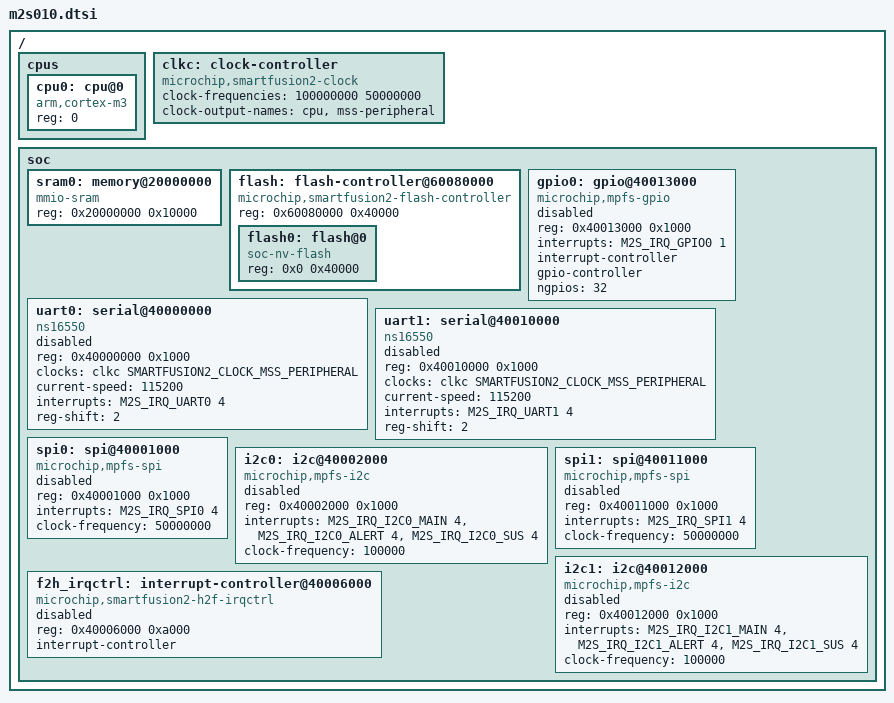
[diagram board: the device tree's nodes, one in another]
/*
 * SPDX-FileCopyrightText: Copyright Bavariamatic GmbH
 * SPDX-License-Identifier: Apache-2.0
 */

#include <arm/armv7-m.dtsi>
#include <zephyr/dt-bindings/clock/microchip-smartfusion2-clock.h>
#include <zephyr/dt-bindings/interrupt-controller/microchip-smartfusion2-irq.h>

/ {
	#address-cells = <1>;
	#size-cells = <1>;

	cpus {
		#address-cells = <1>;
		#size-cells = <0>;

		cpu0: cpu@0 {
			device_type = "cpu";
			compatible = "arm,cortex-m3";
			reg = <0>;
		};
	};

	clkc: clock-controller {
		compatible = "microchip,smartfusion2-clock";
		#clock-cells = <1>;
		clock-frequencies = <100000000 50000000>;
		clock-output-names = "cpu", "mss-peripheral";
	};

	soc {
		sram0: memory@20000000 {
			compatible = "mmio-sram";
			reg = <0x20000000 0x10000>;
		};

		flash: flash-controller@60080000 {
			compatible = "microchip,smartfusion2-flash-controller";
			reg = <0x60080000 0x40000>;
			#address-cells = <1>;
			#size-cells = <1>;
			ranges = <0x0 0x0 0x40000>;

			flash0: flash@0 {
				compatible = "soc-nv-flash";
				reg = <0x0 0x40000>;
				#address-cells = <1>;
				#size-cells = <1>;
				ranges = <0x0 0x0 0x40000>;
			};
		};

		gpio0: gpio@40013000 {
			compatible = "microchip,mpfs-gpio";
			reg = <0x40013000 0x1000>;
			interrupts = <M2S_IRQ_GPIO0 1>;
			interrupt-controller;
			#address-cells = <0>;
			#interrupt-cells = <1>;
			gpio-controller;
			#gpio-cells = <2>;
			ngpios = <32>;
			status = "disabled";
		};

		uart0: serial@40000000 {
			compatible = "ns16550";
			reg = <0x40000000 0x1000>;
			clocks = <&clkc SMARTFUSION2_CLOCK_MSS_PERIPHERAL>;
			current-speed = <115200>;
			interrupts = <M2S_IRQ_UART0 4>;
			reg-shift = <2>;
			status = "disabled";
		};

		uart1: serial@40010000 {
			compatible = "ns16550";
			reg = <0x40010000 0x1000>;
			clocks = <&clkc SMARTFUSION2_CLOCK_MSS_PERIPHERAL>;
			current-speed = <115200>;
			interrupts = <M2S_IRQ_UART1 4>;
			reg-shift = <2>;
			status = "disabled";
		};

		spi0: spi@40001000 {
			compatible = "microchip,mpfs-spi";
			reg = <0x40001000 0x1000>;
			interrupts = <M2S_IRQ_SPI0 4>;
			clock-frequency = <50000000>;
			#address-cells = <1>;
			#size-cells = <0>;
			status = "disabled";
		};

		i2c0: i2c@40002000 {
			compatible = "microchip,mpfs-i2c";
			reg = <0x40002000 0x1000>;
			interrupts = <M2S_IRQ_I2C0_MAIN 4>,
				     <M2S_IRQ_I2C0_ALERT 4>,
				     <M2S_IRQ_I2C0_SUS 4>;
			#address-cells = <1>;
			#size-cells = <0>;
			clock-frequency = <100000>;
			status = "disabled";
		};

		spi1: spi@40011000 {
			compatible = "microchip,mpfs-spi";
			reg = <0x40011000 0x1000>;
			interrupts = <M2S_IRQ_SPI1 4>;
			clock-frequency = <50000000>;
			#address-cells = <1>;
			#size-cells = <0>;
			status = "disabled";
		};

		i2c1: i2c@40012000 {
			compatible = "microchip,mpfs-i2c";
			reg = <0x40012000 0x1000>;
			interrupts = <M2S_IRQ_I2C1_MAIN 4>,
				     <M2S_IRQ_I2C1_ALERT 4>,
				     <M2S_IRQ_I2C1_SUS 4>;
			#address-cells = <1>;
			#size-cells = <0>;
			clock-frequency = <100000>;
			status = "disabled";
		};

		f2h_irqctrl: interrupt-controller@40006000 {
			compatible = "microchip,smartfusion2-h2f-irqctrl";
			reg = <0x40006000 0xa000>;
			interrupt-controller;
			#address-cells = <0>;
			#interrupt-cells = <1>;
			status = "disabled";
		};
	};
};
